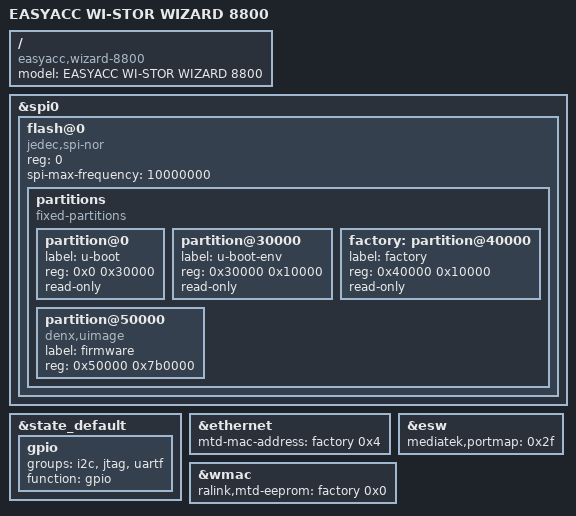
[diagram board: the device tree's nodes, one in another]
#include "rt5350.dtsi"

/ {
	compatible = "easyacc,wizard-8800", "ralink,rt5350-soc";
	model = "EASYACC WI-STOR WIZARD 8800";
};

&spi0 {
	status = "okay";

	flash@0 {
		compatible = "jedec,spi-nor";
		reg = <0>;
		spi-max-frequency = <10000000>;

		partitions {
			compatible = "fixed-partitions";
			#address-cells = <1>;
			#size-cells = <1>;

			partition@0 {
				label = "u-boot";
				reg = <0x0 0x30000>;
				read-only;
			};

			partition@30000 {
				label = "u-boot-env";
				reg = <0x30000 0x10000>;
				read-only;
			};

			factory: partition@40000 {
				label = "factory";
				reg = <0x40000 0x10000>;
				read-only;
			};

			partition@50000 {
				compatible = "denx,uimage";
				label = "firmware";
				reg = <0x50000 0x7b0000>;
			};
		};
	};
};

&state_default {
	gpio {
		groups = "i2c", "jtag", "uartf";
		function = "gpio";
	};
};

&ethernet {
	mtd-mac-address = <&factory 0x4>;
};

&esw {
	mediatek,portmap = <0x2f>;
};

&wmac {
	ralink,mtd-eeprom = <&factory 0x0>;
};
